# SYSCTL_1.0 register map
Vendor: Texas Instruments
Registers are 32-bit, read-write, no defined reset value unless marked. A register's access mark holds for its fields unless they carry their own. Offsets are as the file gives them; [hi:lo] are bit positions; {n}, {i} and the like mark numbered series; 'fields as' and 'values as' point back to an identical list.

## SYSCTL (part 2 of 2)
0x2018 SYSCTL_BOOTDIAG access not given — 32 bit boot diagnostic to Debugss
0x201C SYSCTL_INFRASTATUS1 ro — Infrastructure Status 2
  [0] CRPAD — Customer Return Pad
0x2020 SYSCTL_FWEPROTMAINA access not given — 1 Sector Write-Erase per bit starting at address 0x0 of flash
0x2024 SYSCTL_FWEPROTMAINB0 access not given — 8xSector Write-Erase per bit starting at address 0x0 of flash
0x2038 SYSCTL_CSC — Customer Startup Code Exists
  [0] DISABLE — BOOTCODE writes 1 to remove CSC handling, default is CSC exists and will be executed
    1=TRUE (CSC DISABLED)
0x203C SYSCTL_DBGCSC — Debug Customer Startup Code
  [0] ON — BOOTCODE writes 1 to indicate that Debug Of CSC is available, left unwritten there will be no CSC debug possible
    1=TRUE
0x2040 SYSCTL_JTAGUSERCODE access not given — JTAG USERCODE
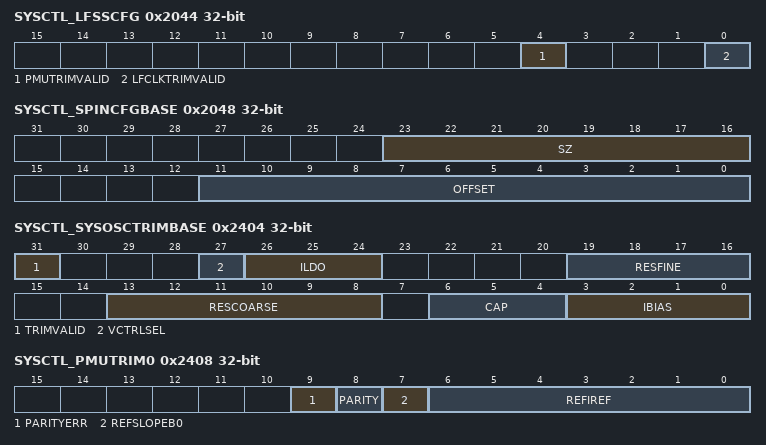
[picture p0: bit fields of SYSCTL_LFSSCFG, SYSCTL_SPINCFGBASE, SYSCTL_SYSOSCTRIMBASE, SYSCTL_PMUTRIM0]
0x2044 SYSCTL_LFSSCFG — LFSS Configuration control
  [4] PMUTRIMVALID — PMU TRIM For VBAT of LFSS is Valid
  [0] LFCLKTRIMVALID — LFCLK TRIM For LFSS is Valid
0x2048 SYSCTL_SPINCFGBASE ro — SPIN Configuration Offset and Size
  [23:16] SZ — Size in number of words of SPIN region including SPINCRC
  [11:0] OFFSET — Offset to start of SPINCFG from TRIMCFG base
0x204C SYSCTL_DEVICE_SUBTYPE — Device Subtype
  [15:0] VALUE
    0x5555=FS (Device is Field Securable); 0x9999=FA (Device Failure Analysis); 0xAAAA=KP (Device Key Provisioned); 0xABCD=SE (Device Security Enforced for all other values)
0x2400 SYSCTL_DMATRIMUNLOCK access not given — DMA TRIM Unlock
0x2404 SYSCTL_SYSOSCTRIMBASE — SYSOSC Trim Values for frequency when change from disable to enable, generally 32MHz
  [31] TRIMVALID — TRIM Data Valid- used to trigger FSM
  [27] VCTRLSEL — VCTRL SEL used potentially needed for FCL mode. Default 0
  [26:24] ILDO — ILDO TRIM -- Only 1 value, Not frequency dependent
  [19:16] RESFINE — Resister Coarse TRIM - Changes per frequency target
  [13:8] RESCOARSE — Resister Coarse TRIM - Changes per frequency target
  [6:4] CAP — CAP TRIM - Changes per frequency target
  [3:0] IBIAS — IBIAS TRIM - Only 1 value, not frequency dependent
0x2408 SYSCTL_PMUTRIM0 access per field — PMU TRIM 0
  [9] PARITYERR ro — Parity Error for PMUTRIM0
  [8] PARITY rw — Parity for PMUTRIM0
  [7] REFSLOPEB0 rw — Reference Slope TRIM Bit0
  [6:0] REFIREF rw — Reference IREF TRIM
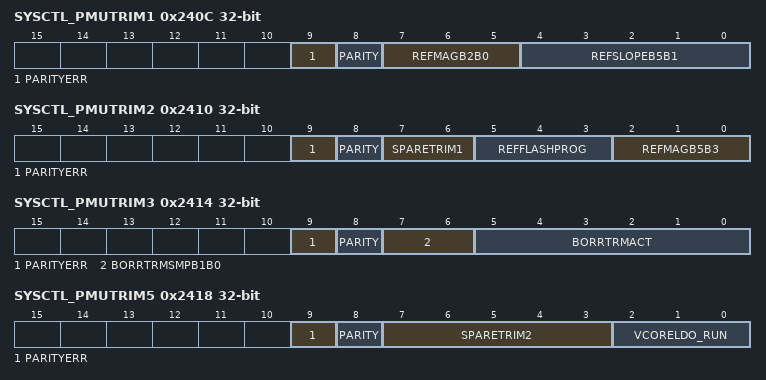
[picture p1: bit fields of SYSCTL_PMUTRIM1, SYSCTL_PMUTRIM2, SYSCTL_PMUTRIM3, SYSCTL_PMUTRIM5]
0x240C SYSCTL_PMUTRIM1 access per field — PMU TRIM 1
  [9] PARITYERR ro — Parity Error for PMUTRIM1
  [8] PARITY rw — Parity for PMUTRIM1
  [7:5] REFMAGB2B0 rw — Reference MAG TRIM Bit2_0
  [4:0] REFSLOPEB5B1 rw — Reference Slope TRIM Bit5_1
0x2410 SYSCTL_PMUTRIM2 access per field — PMU TRIM 2
  [9] PARITYERR ro — Parity Error for PMUTRIM2
  [8] PARITY rw — Parity for PMUTRIM2
  [7:6] SPARETRIM1 rw
  [5:3] REFFLASHPROG rw — Reference Flash Programming
  [2:0] REFMAGB5B3 rw — Reference MAG TRIM Bit5_3
0x2414 SYSCTL_PMUTRIM3 access per field — PMU TRIM 3
  [9] PARITYERR ro — Parity Error for PMUTRIM3
  [8] PARITY rw — Parity for PMUTRIM3
  [7:6] BORRTRMSMPB1B0 rw — BOR R-TRIM for Sampled mode1_0
  [5:0] BORRTRMACT rw — BOR R-TRIM for Active mode
0x2418 SYSCTL_PMUTRIM5 access per field — PMU TRIM 5
  [9] PARITYERR ro — Parity Error for PMUTRIM5
  [8] PARITY rw — Parity for PMUTRIM5
  [7:3] SPARETRIM2 rw
  [2:0] VCORELDO_RUN rw — Voltage Setting for RUN mode
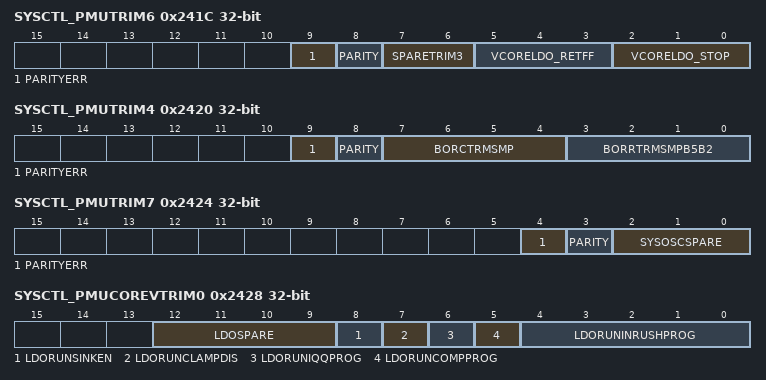
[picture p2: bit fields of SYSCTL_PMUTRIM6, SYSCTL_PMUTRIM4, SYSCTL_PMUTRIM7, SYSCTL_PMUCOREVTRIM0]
0x241C SYSCTL_PMUTRIM6 access per field — PMU TRIM 6
  [9] PARITYERR ro — Parity Error for PMUTRIM6
  [8] PARITY rw — Parity for PMUTRIM6
  [7:6] SPARETRIM3 rw
  [5:3] VCORELDO_RETFF rw — Voltage Setting for retention flop during STOP mode
  [2:0] VCORELDO_STOP rw — Voltage Setting for 10 percent OPP in STOP-STANDBY mode
0x2420 SYSCTL_PMUTRIM4 access per field — PMU TRIM 4
  [9] PARITYERR ro — Parity Error for PMUTRIM4
  [8] PARITY rw — Parity for PMUTRIM4
  [7:4] BORCTRMSMP rw — BOR C-TRIM for Sampled mode3_0
  [3:0] BORRTRMSMPB5B2 rw — BOR R-TRIM for Sampled mode5_2
0x2424 SYSCTL_PMUTRIM7 access per field — PMU TRIM 7
  [4] PARITYERR ro — Parity Error for PMUTRIM7
  [3] PARITY rw — Parity for PMUTRIM7
  [2:0] SYSOSCSPARE rw — Sysosc LDO Spare TRIM
0x2428 SYSCTL_PMUCOREVTRIM0 — PMU CORE VOLTAGE TRIM 0
  [12:9] LDOSPARE — LDO RUN SPARE
  [8] LDORUNSINKEN
  [7] LDORUNCLAMPDIS
  [6] LDORUNIQQPROG
  [5] LDORUNCOMPPROG
  [4:0] LDORUNINRUSHPROG
0x242C SYSCTL_FLASHPUMPTRIML access not given — Flash Pump TRIM-CFG Bits 31...0
0x2430 SYSCTL_FLASHPUMPTRIMH — Flash Pump TRIM-CFG Bits 39...32
  [7:0] DATA — Flash IP determines usage
0x2434 SYSCTL_FLASHBANK0TRIM access not given — $btname TRIM-CFG
0x2438 SYSCTL_FLASHBANK0MPTRIM — $brname Flash MP Trim
  [7:0] DATA — MP Trim Bits
0x243C SYSCTL_FLASHBANK0REPAIR — $brname Flash Repair
  [27:0] DATA — Repair Bits
0x2440 SYSCTL_FLASHBANK1TRIM access not given — $btname TRIM-CFG
0x2444 SYSCTL_FLASHBANK1MPTRIM — $brname Flash MP Trim
  [7:0] DATA — MP Trim Bits
0x2448 SYSCTL_FLASHBANK1REPAIR — $brname Flash Repair
  [27:0] DATA — Repair Bits
0x244C SYSCTL_FLASHBANK2TRIM access not given — $btname Data Bank TRIM-CFG
0x2450 SYSCTL_FLASHBANK2MPTRIM — $brname Flash MP TRIM
  [7:0] DATA — Data Bank MP TRIM Bits
0x2454 SYSCTL_FLASHBANK2REPAIR — $brname Flash Repair
  [27:0] DATA — Data Bank Repair Bits
0x2458 SYSCTL_SRAMREPAIR0 access not given — SRAM Repair 1
0x245C SYSCTL_SRAMREPAIR access not given — SRAM Repair
0x2460 SYSCTL_FLASHSRAMCFG — Flash and SRAM Configuration
  [31] FLTRIMDONE — 1: Flash TRIM bits loaded 0: TRIM unwritten
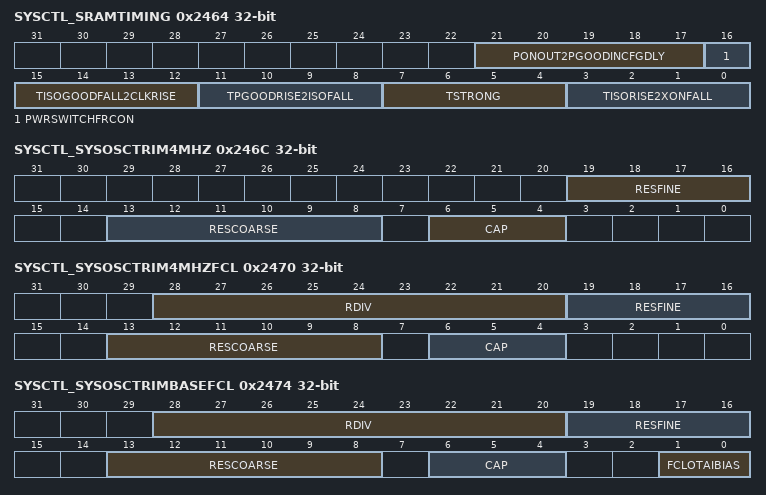
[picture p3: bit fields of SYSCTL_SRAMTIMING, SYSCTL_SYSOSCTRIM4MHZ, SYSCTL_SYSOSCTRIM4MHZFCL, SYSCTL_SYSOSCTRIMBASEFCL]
0x2464 SYSCTL_SRAMTIMING — SRAM timing MMR for ESRAM controller, based on 4MHz
  [21:17] PONOUT2PGOODINCFGDLY — Programmable delay for power switch PONOUT to PGOODIN
  [16] PWRSWITCHFRCON — Debug option to force SVT SRAM PWR Switches always on
  [15:12] TISOGOODFALL2CLKRISE — ISO GOOD FALL to CLKRISE, spec 250ns (boot 500ns)
  [11:8] TPGOODRISE2ISOFALL — PGOOD RISE to ISO FALL, spec 750ns (boot 1500ns)
  [7:4] TSTRONG — Driver Weak to Stong timing, spec 1000ns (boot 1500ns)
  [3:0] TISORISE2XONFALL — ISO Rise to any ON FALL, spec 500ns (boot 750ns)
0x2468 SYSCTL_MCORELDOCFG — LDO Voltage Settings
  [27:24] STOP2RUNDLY — Delay value in usec for STOP voltage to STEP voltage
0x246C SYSCTL_SYSOSCTRIM4MHZ — SYSOSC Trim Values for 4MHz target
  [19:16] RESFINE — Resister Coarse TRIM - Changes per frequency target
  [13:8] RESCOARSE — Resister Coarse TRIM - Changes per frequency target
  [6:4] CAP — CAP TRIM - Changes per frequency target
0x2470 SYSCTL_SYSOSCTRIM4MHZFCL — SYSOSC Trim Values for 4MHz target with FCL enabled
  [28:20] RDIV — FCL RDIV TRIM - Changes per frequency target
  [19:16] RESFINE — Resister Coarse TRIM - Changes per frequency target
  [13:8] RESCOARSE — Resister Coarse TRIM - Changes per frequency target
  [6:4] CAP — CAP TRIM - Changes per frequency target
0x2474 SYSCTL_SYSOSCTRIMBASEFCL — SYSOSC Trim Values for 32MHz target with FCL enabled
  [28:20] RDIV — FCL RDIV TRIM - Changes per frequency target
  [19:16] RESFINE — Resister Fine TRIM - Changes per frequency target
  [13:8] RESCOARSE — Resister Coarse TRIM - Changes per frequency target
  [6:4] CAP — CAP TRIM - Changes per frequency target
  [1:0] FCLOTAIBIAS — FCL IBIAS TRIM, Not frequency dependent
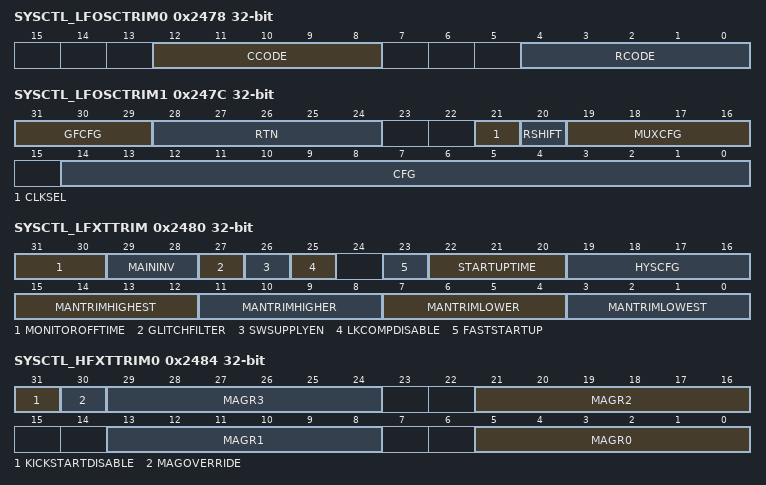
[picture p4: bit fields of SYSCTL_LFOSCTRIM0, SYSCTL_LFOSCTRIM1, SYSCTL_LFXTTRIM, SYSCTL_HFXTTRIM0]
0x2478 SYSCTL_LFOSCTRIM0 — LFOSC TRIM values
  [12:8] CCODE — LFOSC Cap Frequency Trim
  [4:0] RCODE — LFOSC Res Frequency Trim
0x247C SYSCTL_LFOSCTRIM1 — LFOSC TRIM values
  [31:29] GFCFG — LFXT GFCFG - This is hardwired 0 if no LFXT present
  [28:24] RTN — LFOSC Noise Trim
  [21] CLKSEL — 0: divide LFOSC by 2 to give 32KHz, 1: pass through 64KHz
  [20] RSHIFT — LFOSC RSHIFT Trim
  [19:16] MUXCFG — LFOSC Mux CFG Trim
  [14:0] CFG — LFOSC CFG Trim
0x2480 SYSCTL_LFXTTRIM — LFXT TRIM values
  [31:30] MONITOROFFTIME — XT Monitor Off Time Trim
  [29:28] MAININV — LFXT Main Inverter Strength
  [27] GLITCHFILTER — Glitch Filter Enable
    0=DISABLE; 1=ENABLE
  [26] SWSUPPLYEN — LFXT SW Supply Enable
  [25] LKCOMPDISABLE — LFXT Leakage Comp Disable
  [23] FASTSTARTUP — LFXT Fast Startup Select
  [22:20] STARTUPTIME — LFXT Startup Time
  [19:16] HYSCFG — LFXT Hysterisys Config
  [15:12] MANTRIMHIGHEST — LFXT Man Reg Trim Highest Power
  [11:8] MANTRIMHIGHER — LFXT Man Reg Trim Higher Power
  [7:4] MANTRIMLOWER — LFXT Man Reg Trim Lower Power
  [3:0] MANTRIMLOWEST — LFXT Man Reg Trim Lowest Power
0x2484 SYSCTL_HFXTTRIM0 — HFXT TRIM and Override
  [31] KICKSTARTDISABLE — DISABLE Kickstart
    0=FALSE; 1=TRUE
  [30] MAGOVERRIDE — Use this TRIM value instead of hardwired
    0=DISABLE; 1=ENABLE
  [8n+5:8n] MAGR{n} (n=0..3) — Value for MAG TRIM Range {n}
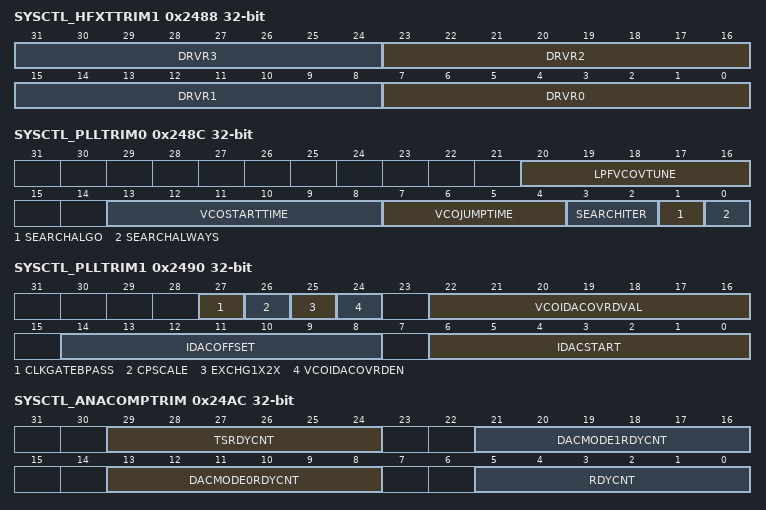
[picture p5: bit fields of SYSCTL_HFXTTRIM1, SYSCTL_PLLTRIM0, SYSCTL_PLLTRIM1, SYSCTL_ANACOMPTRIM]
0x2488 SYSCTL_HFXTTRIM1 — HFXT TRIM and Override
  [8n+7:8n] DRVR{n} (n=0..3) — Value for DRV TRIM Range {n}
0x248C SYSCTL_PLLTRIM0 — PLL TRIM and Override
  [20:16] LPFVCOVTUNE — LPF VCOVTUNE NOM Value
  [13:8] VCOSTARTTIME — VCO Start Settling Time in HFXT 48MHz - this comes before STARTTIME-STARTTIMELP
  [7:4] VCOJUMPTIME — VCO Freq Jump Settling Time
  [3:2] SEARCHITER — Search iterations to perform
    0=OneIteration; 1=TwoIteration; 2=ThreeIteration; 3=FourIteration
  [1] SEARCHALGO — Select Search Mode Algorithm
    0=ALG1; 1=ALG2
  [0] SEARCHALWAYS — Force Freq Search to ALWAYS be performed
    0=DISABLE; 1=ENABLE
0x2490 SYSCTL_PLLTRIM1 — PLL TRIM and Override
  [27] CLKGATEBPASS — Clock Gating Bypass added to SPARE MMR bit 1 port
    0=DISABLE; 1=ENABLE
  [26] CPSCALE — CP Scale added to SPARE MMR bit 0 port
    0=DISABLE; 1=ENABLE
  [25] EXCHG1X2X — Exchange 1X and 2X clock paths - Experimental
    0=DISABLE; 1=ENABLE
  [24] VCOIDACOVRDEN — VCO Feq IDAC mcode override enable
    0=DISABLE; 1=ENABLE
  [22:16] VCOIDACOVRDVAL — VCO Feq IDAC mcode override val
  [14:8] IDACOFFSET — IDAC Offset Value
  [6:0] IDACSTART — IDAC Start Value
0x2494 SYSCTL_M33ADC12B0INLTRIM0 access not given — Bits 31..0 of ADC INL TRIM Instance 0
0x2498 SYSCTL_M33ADC12B0INLTRIM1 — Bits 62..32 of ADC INL TRIM Instance 0
  [30:0] VALUE — Bits 62..32 of ADC INL TRIM
0x249C SYSCTL_M33ADC12B0OFFSETTRIM — Bits 7..0 of ADC OFFSET TRIM Instance 0
  [7:0] VALUE — Bits 62..32 of ADC OFFSET TRIM
0x24A0 SYSCTL_M33ADC12B1INLTRIM0 access not given — Bits 31..0 of ADC INL TRIM Instance 0
0x24A4 SYSCTL_M33ADC12B1INLTRIM1 — Bits 62..32 of ADC INL TRIM Instance 0
  [30:0] VALUE — Bits 62..32 of ADC INL TRIM
0x24A8 SYSCTL_M33ADC12B1OFFSETTRIM — Bits 7..0 of ADC OFFSET TRIM Instance 1
  [7:0] VALUE — Bits 62..32 of ADC OFFSET TRIM
0x24AC SYSCTL_ANACOMPTRIM — Common Trims for Anacomp
  [29:24] TSRDYCNT — TempSense Ready Count in 1 usec resolution
  [21:16] DACMODE1RDYCNT — DAC Ready Count in 1 usec resolution
  [13:8] DACMODE0RDYCNT — DAC Ready Count in 250ns usec resolution
  [5:0] RDYCNT — Ready Count in 1 usec resolution
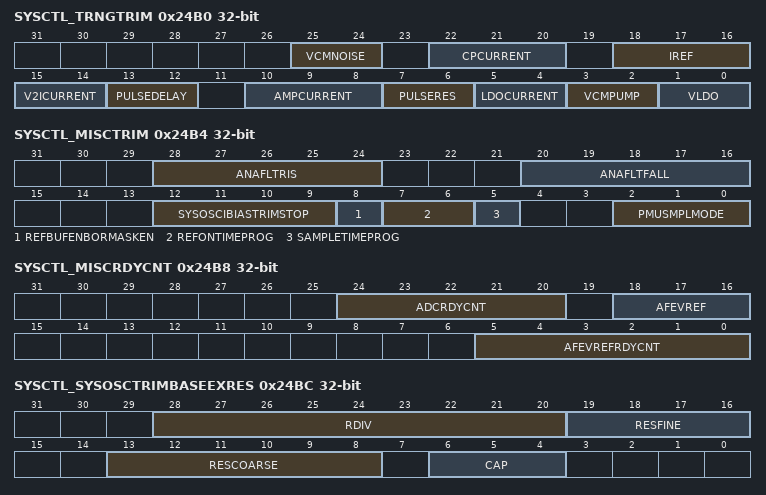
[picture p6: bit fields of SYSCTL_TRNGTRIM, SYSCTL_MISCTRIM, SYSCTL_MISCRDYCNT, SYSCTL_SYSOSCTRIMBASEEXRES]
0x24B0 SYSCTL_TRNGTRIM — Trim for TRNG
  [25:24] VCMNOISE — TRNG VCM Noise TRIM
  [22:20] CPCURRENT — TRNG CP Current TRIM
  [18:16] IREF — TRNG IREF TRIM
  [15:14] V2ICURRENT — TRNG V2i Current TRIM
  [13:12] PULSEDELAY — TRNG Pulse Delay TRIM
  [10:8] AMPCURRENT — TRNG Amp Current TRIM
  [7:6] PULSERES — TRNG Pulse Res TRIM
  [5:4] LDOCURRENT — TRNG LDO Current TRIM
  [3:2] VCMPUMP — TRNG VCM Pump TRIM
  [1:0] VLDO — TRNG VLDO TRIM
0x24B4 SYSCTL_MISCTRIM — Various Small TRIM
  [28:24] ANAFLTRIS — Analog GlitchFilter Rising Trim
  [20:16] ANAFLTFALL — Analog GlitchFilter Falling Trim
  [12:9] SYSOSCIBIASTRIMSTOP — IBIAS TRIM - in STOP mode, oscillator accuracy
  [8] REFBUFENBORMASKEN — BOR Mask Enable
    0=BORMASKDISABLE (BOR Masking disabled when REFBUF is enabled); 1=BORMASKENABLE (BOR Masking enabled when REFBUF is enabled)
  [7:6] REFONTIMEPROG — PMU Ref On Time Programmability TRIM for STANDBY Mode
    {v}=REFONTIME{v+3}CLOCKS (Ref On Time is {v+3} Clocks) (v=0..3)
  [5] SAMPLETIMEPROG — PMU Sample Time Programmability TRIM for STANDBY Mode
    0=SMPLTIME1CLOCK (Sample Time is 1 Clock); 1=SMPLTIME2CLOCKS (Sample Time is 2 Clocks)
  [2:0] PMUSMPLMODE — PMU REF/BOR Sample Periode TRIM for STANDBY Mode
    0=SMPL8MS (Sample Periode is 8ms); 1=SMPL16MS (Sample Periode is 16ms); 2=SMPL32MS (Sample Periode is 32ms); 3=SMPL48MS (Sample Periode is 48ms); 4=SMPL64MS (Sample Periode is 64ms); 5=SMPL80MS (Sample Periode is 80ms); 6=SMPL100MS (Sample Periode is 100ms); 7=SMPL125MS (Sample Periode is 125ms)
0x24B8 SYSCTL_MISCRDYCNT — Various Small RDY CNT or other familiy TRIM
  [24:20] ADCRDYCNT — Ready Count in 1 usec resolution
  [18:16] AFEVREF — VREF TRIM
  [5:0] AFEVREFRDYCNT — VREF Ready Count Nano is in 1 usec, Micro in 8 usec resolution
0x24BC SYSCTL_SYSOSCTRIMBASEEXRES — SYSOSC Trim Values for BASE frequency external resistor FCL
  [28:20] RDIV — External Resistor feature Not used
  [19:16] RESFINE — External Resistor feature Not used
  [13:8] RESCOARSE — External Resistor feature Not used
  [6:4] CAP — External Resistor feature Not used
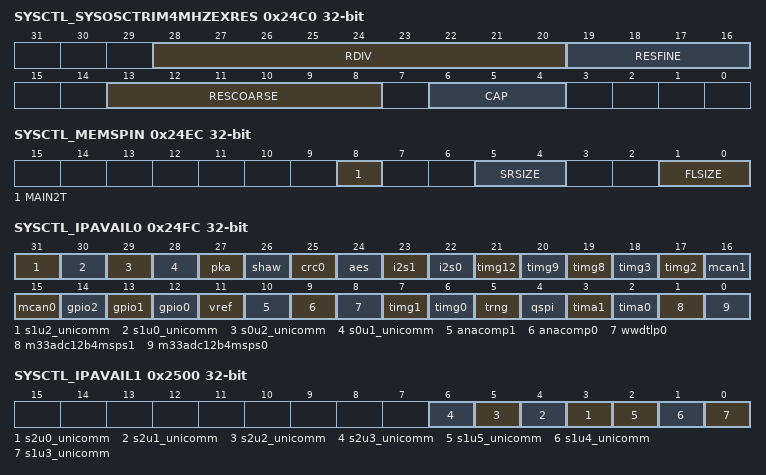
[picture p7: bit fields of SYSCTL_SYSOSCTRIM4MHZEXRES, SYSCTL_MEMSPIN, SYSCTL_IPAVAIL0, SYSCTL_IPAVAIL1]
0x24C0 SYSCTL_SYSOSCTRIM4MHZEXRES — SYSOSC Trim Values for 4MHz frequency external resistor FCL
  fields as SYSCTL_SYSOSCTRIMBASEEXRES
0x24C4 SYSCTL_ANACOMP0TRIM — Per Instance TRIM for ANACOMP0
  [6:0] DATA — TRIM value
0x24C8 SYSCTL_ANACOMP1TRIM — Per Instance TRIM for ANACOMP1
  [6:0] DATA — TRIM value
0x24CC SYSCTL_VBATPMUTRIM0 access not given — VBAT PMU TRIM lower 32bits
0x24D0 SYSCTL_VBATPMUTRIM1 — VBAT PMU TRIM Bits 42-32
  [10:0] DATA — Bits 42-32 VBAT PMU TRIM
0x24D4 SYSCTL_M33C1SPARETRIM1 access not given — M33C1 Spare TRIM1
0x24D8 SYSCTL_M33C1SPARETRIM2 access not given — M33C1 Spare TRIM2
0x24DC SYSCTL_ULLSYSOSC — SYSOSC Spare TRIM
  [2:0] SPARE — Sysosc Spare Trim
0x24E0 SYSCTL_M33C1SPAREREG access not given — Spare Register Read only
0x24E4 SYSCTL_PROBECRC access not given — FINAL 32 bit CRC of the PROBE TRIM load
0x24E8 SYSCTL_SPINUNLOCK access not given — SPIN Region Unlock Signiture: 0x5F689B9D always reads this value
0x24EC SYSCTL_MEMSPIN — Flash and SRAM Configuration
  [8] MAIN2T — 1: Main (nonmain) are 2T access 0: Main (nonmain) are 1T access
  [5:4] SRSIZE — SRAM Paper Spin 0: Full size, 1: 1/2, 2: 1/4
  [1:0] FLSIZE — Flash Paper Spin 0: Full size, 1: 1/2, 2: 1/4
0x24F0 SYSCTL_PADNOTAVAIL0 access not given — PAD Exist for IOMUX
0x24F4 SYSCTL_PADNOTAVAIL1 access not given — PAD Exist for IOMUX
0x24F8 SYSCTL_PADNOTAVAIL2 — PAD Exist for IOMUX
  [28:0] DATA — Padexists Vector bits- 0: Pad Available 1: Pad Not Available
0x24FC SYSCTL_IPAVAIL0 — IP Available Paper Spin
  [all] fields
    0=NOTAVAILABLE; 1=AVAILABLE
  [31] s1u2_unicomm — Bit field is not used
  [30] s1u0_unicomm — Bit field is not used
  [29] s0u2_unicomm — Bit field is not used
  [28] s0u1_unicomm — Bit field is not used
  [27] pka — Peripheral Instance Available
  [26] shaw — Peripheral Instance Available
  [25] crc0 — Peripheral Instance Available
  [24] aes — Bit field is not used
  [23] i2s1 — Bit field is not used
  [22] i2s0 — Bit field is not used
  [21] timg12 — Bit field is not used
  [20] timg9 — Bit field is not used
  [19] timg8 — Bit field is not used
  [18] timg3 — Bit field is not used
  [17] timg2 — Bit field is not used
  [16] mcan1 — Peripheral Instance Available
  [15] mcan0 — Peripheral Instance Available
  [14] gpio2 — Bit field is not used
  [13] gpio1 — Bit field is not used
  [12] gpio0 — Bit field is not used
  [11] vref — Bit field is not used
  [10] anacomp1 — Bit field is not used
  [9] anacomp0 — Bit field is not used
  [8] wwdtlp0 — Bit field is not used
  [7] timg1 — Bit field is not used
  [6] timg0 — Bit field is not used
  [5] trng — Bit field is not used
  [4] qspi — Bit field is not used
  [3] tima1 — Bit field is not used
  [2] tima0 — Bit field is not used
  [1] m33adc12b4msps1 — Bit field is not used
  [0] m33adc12b4msps0 — Bit field is not used
0x2500 SYSCTL_IPAVAIL1 — IP Available Paper Spin
  [all] fields
    0=NOTAVAILABLE; 1=AVAILABLE
  [n+3] s2u{n}_unicomm (n=0..3) — Peripheral Instance Available
  [2] s1u5_unicomm — Peripheral Instance Available
  [1] s1u4_unicomm — Peripheral Instance Available
  [0] s1u3_unicomm — Peripheral Instance Available
0x2504 SYSCTL_FUNCPSPIN — Functional Paper Spin Options
  [0] MCANFD — MCAN FD enabled
0x2508 SYSCTL_TRIMCRC access not given — FINAL 32 bit CRC of the SPIN load
0x2800 SYSCTL_MGMT_M33ADC12B4MSPS1_PWREN — IP Enable Register
  [0] ENABLE — IP Enable
    0=Disable; 1=Enable
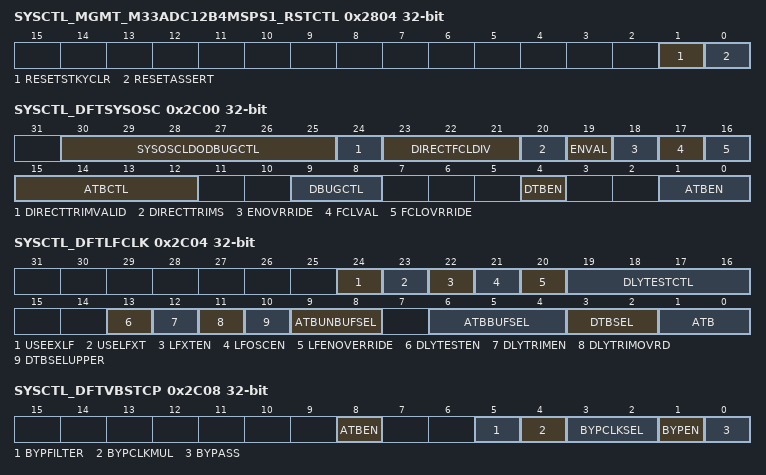
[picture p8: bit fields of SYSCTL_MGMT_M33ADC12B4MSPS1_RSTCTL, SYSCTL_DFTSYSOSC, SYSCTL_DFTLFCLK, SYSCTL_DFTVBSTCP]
0x2804 SYSCTL_MGMT_M33ADC12B4MSPS1_RSTCTL — Power Control Register - Write Only Register, Always Read as 0
  [1] RESETSTKYCLR — Clear the RESET STICKY Bit
    1=Clear
  [0] RESETASSERT — Assert Reset to IP Domain.
    1=Do
0x2814 SYSCTL_MGMT_M33ADC12B4MSPS1_STAT ro — IP State Register - Read Only
  [16] RESETSTKY — IP has been Reset
    0=clear; 1=Set
0x2C00 SYSCTL_DFTSYSOSC — DFT Control for SYSOSC
  [30:25] SYSOSCLDODBUGCTL — SYSOSC LDO DBUG CTL Direct to MSIP
  [24] DIRECTTRIMVALID — TRIMVALID MSIP input value when DIRECTTRIMS is 1
  [23:21] DIRECTFCLDIV — FCL DIV value when DIRECTTRIMS is 1
  [20] DIRECTTRIMS — MUX SYSOSCBASE MMR values directly to MSIP input and hold SWITCHFREQ 1
  [19] ENVAL — Override Value for the functional Enable into the MSIP
  [18] ENOVRRIDE — Override the functional Enable with ENVAL into the MSIP
  [17] FCLVAL — Override Value for the functional FCL Enable into the MSIP
  [16] FCLOVRRIDE — Override the functional FCL Enable with FCLVAL into the MSIP
  [15:12] ATBCTL — ATB Control - Direct to MSIP
  [9:8] DBUGCTL — Debug Control - Direct to MSIP
  [4] DTBEN — Enable DTB Structure - Direct to MSIP
    0=DISABLE; 1=ENABLE
  [1:0] ATBEN — Enable ATB Structure - Direct to MSIP
0x2C04 SYSCTL_DFTLFCLK — DFT Control for LFCLK Hard Macro
  [24] USEEXLF — Value for USEEXLF when LFENOVERRIDE is set
  [23] USELFXT — Value for USELFXT when LFENOVERRIDE is set
  [22] LFXTEN — Value for LFXT_EN when LFENOVERRIDE is set
  [21] LFOSCEN — Value for LFOSC_EN when LFENOVERRIDE is set
  [20] LFENOVERRIDE — Override the functional LFOSC - LFXT enable
  [19:16] DLYTESTCTL — Delay Cell Test CTL - Direct to MSIP
  [13] DLYTESTEN — WHEN DLYTRIMOVRD - DLYTESTEN - ELSE 0 for Delay Cell Test Enable
  [12] DLYTRIMEN — WHEN DLYTRIMOVRD - DLYTRIMEN - ELSE 1 for Delay Cell Trim Enable
  [11] DLYTRIMOVRD — Delay Cell Trim OVERRIDE control
  [10] DTBSELUPPER — DTB Select for Upper 4 bits of DTBO[11:0] of hard macro
  [9:8] ATBUNBUFSEL — ATB Buffered Signal Select - Direct to MSIP
  [6:4] ATBBUFSEL — ATB Buffered Signal Select - Direct to MSIP
  [3:2] DTBSEL — DTB Select at hard macro - Direct to MSIP
  [1:0] ATB — Bit1: enables buffered path, Bit0 enables unbuffered path - Direct to MSIP
0x2C08 SYSCTL_DFTVBSTCP — DFT for VBOOST Charge Pump
  [8] ATBEN — This forces CPUMP enabled as part of the larger enable equation it is not the dedicated override
    0=DISABLE; 1=ENABLE
  [5] BYPFILTER — No filter makes power up faster
    0=DISABLE; 1=ENABLE
  [4] BYPCLKMUL — Multiply CP clk by 8
    0=DISABLE; 1=ENABLE
  [3:2] BYPCLKSEL — CP Clock Select
    0=CLK4MHZ; 2=CLK32KHZ; 3=DTBI0
  [1] BYPEN — EN to Hard Macro
    0=DISABLE; 1=ENABLE
  [0] BYPASS — Override enable for BYPCLKMUL, BYPFILTER, BYPEN, BYPCLKSEL
    0=DISABLE; 1=ENABLE
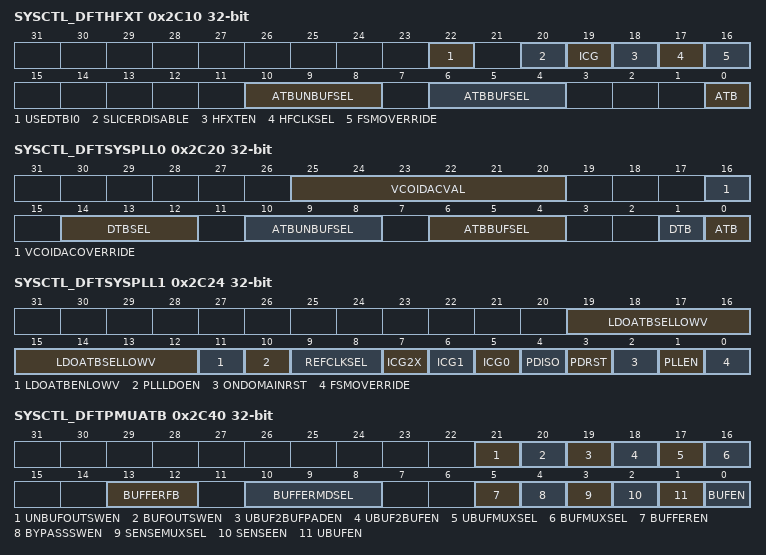
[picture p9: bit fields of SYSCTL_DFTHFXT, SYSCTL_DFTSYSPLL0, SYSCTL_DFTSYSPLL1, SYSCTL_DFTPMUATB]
0x2C10 SYSCTL_DFTHFXT — DFT Control for HFXT
  [22] USEDTBI0 — Use DTBI[0] as the HFCLK output - does not require FSMOVERRIDE
    0=FALSE; 1=TRUE
  [20] SLICERDISABLE — Turn off slicer - Direct to MSIP
    0=FALSE; 1=TRUE
  [19] ICG — Override value when FSMOVERRIDE to turn HFCLK related ICGs ON qualified with HFCLKSEL
    0=DISABLE; 1=ENABLE
  [18] HFXTEN — Override value when FSMOVERRIDE for HFXT ENABLE to Hard Macro
    0=DISABLE; 1=ENABLE
  [17] HFCLKSEL — Override value when FSMOVERRIDE for High Frequency Oscillator Source(HFCLK)
    0=HFXT; 1=EXTHF
  [16] FSMOVERRIDE — Override outputs of HFCLK FSM-ATTEST must also be TRUE
    0=DISABLE; 1=ENABLE
  [10:8] ATBUNBUFSEL — ATB Buffered Signal Select - Direct to MSIP
  [6:4] ATBBUFSEL — ATB Buffered Signal Select - Direct to MSIP
  [0] ATB — Enable ATB Structure - Direct to MSIP
    0=DISABLE; 1=ENABLE
0x2C20 SYSCTL_DFTSYSPLL0 — DFT Control for SYSPLL
  [25:20] VCOIDACVAL — Override Value For VCO Freq Idac Code - Direct to MSIP
  [16] VCOIDACOVERRIDE — Override Enable For VCO Freq Idac Code - Direct to MSIP
    0=DISABLE; 1=ENABLE
  [14:12] DTBSEL — DTB Signal Select - Direct to MSIP
  [10:8] ATBUNBUFSEL — ATB UnBuffered Signal Select - Direct to MSIP
  [6:4] ATBBUFSEL — ATB Buffered Signal Select - Direct to MSIP
  [1] DTB — Enable DTB Structure - Direct to MSIP
    0=DISABLE; 1=ENABLE
  [0] ATB — Enable ATB Structure - Direct to MSIP
    0=DISABLE; 1=ENABLE
0x2C24 SYSCTL_DFTSYSPLL1 — DFT Control for SYSPLL
  [19:12] LDOATBSELLOWV — LDO ATB mux selection - Direct to MSIP
  [11] LDOATBENLOWV — LDO ATB mux enable - Direct to MSIP
  [10] PLLLDOEN — Override value when FSMOVERRIDE for PLL LDO ENABLE to PLL
    0=DISABLE; 1=ENABLE
  [9:8] REFCLKSEL — Override value when FSMOVERRIDE Override value to select Ref Clk
    0=SYSOSC; 1=HFCLK; 2=DTBI0
  [7] ICG2X — Override value when FSMOVERRIDE Override value to turn PLL ICGCLK2X ON
    0=DISABLE; 1=ENABLE
  [6] ICG1 — Override value when FSMOVERRIDE Override value to turn PLL ICGCLK1 ON
    0=DISABLE; 1=ENABLE
  [5] ICG0 — Override value when FSMOVERRIDE Override value to turn PLL ICGCLK0 ON
    0=DISABLE; 1=ENABLE
  [4] PDISO — Override value when FSMOVERRIDE Assert ISO PD to the hard macro
    0=DEASSERT; 1=ASSERT
  [3] PDRST — Override value when FSMOVERRIDE Assert RST PD to the hard macro
    0=DEASSERT; 1=ASSERT
  [2] ONDOMAINRST — Override value when FSMOVERRIDE Assert ONDOMAIN RST to the hard macro
    0=DEASSERT; 1=ASSERT
  [1] PLLEN — Override value when FSMOVERRIDE for PLL ENABLE to PLL
    0=DISABLE; 1=ENABLE
  [0] FSMOVERRIDE — Override outputs of PLL FSM-ATTEST must also be TRUE
    0=DISABLE; 1=ENABLE
0x2C40 SYSCTL_DFTPMUATB — DFT Control for PMU ATB
  [21] UNBUFOUTSWEN
    0=DISABLE; 1=ENABLE
  [20] BUFOUTSWEN
    0=DISABLE; 1=ENABLE
  [19] UBUF2BUFPADEN
    0=DISABLE; 1=ENABLE
  [18] UBUF2BUFEN
    0=DISABLE; 1=ENABLE
  [17] UBUFMUXSEL
    0=DISABLE; 1=ENABLE
  [16] BUFMUXSEL
    0=DISABLE; 1=ENABLE
  [13:12] BUFFERFB
  [10:8] BUFFERMDSEL
  [5] BUFFEREN
    0=DISABLE; 1=ENABLE
  [4] BYPASSSWEN
    0=DISABLE; 1=ENABLE
  [3] SENSEMUXSEL
    0=DISABLE; 1=ENABLE
  [2] SENSEEN
    0=DISABLE; 1=ENABLE
  [1] UBUFEN — ATB UnBuffered Output Enable
    0=DISABLE; 1=ENABLE
  [0] BUFEN — ATB Buffered Output Enable
    0=DISABLE; 1=ENABLE
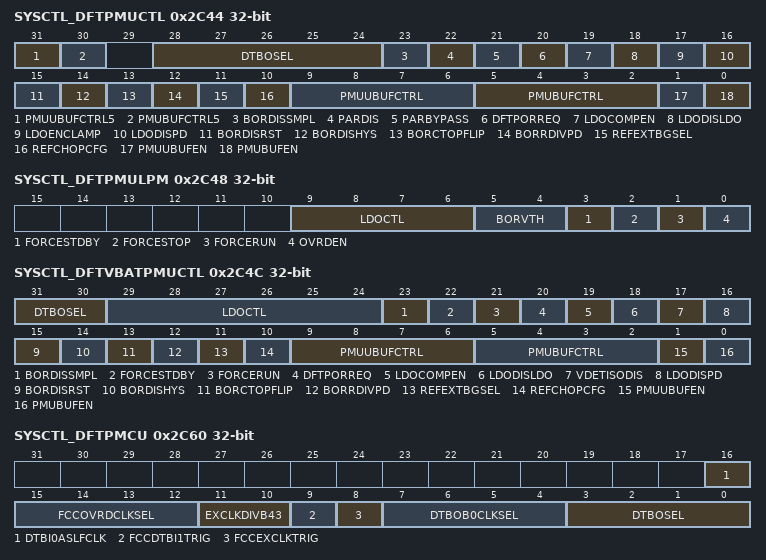
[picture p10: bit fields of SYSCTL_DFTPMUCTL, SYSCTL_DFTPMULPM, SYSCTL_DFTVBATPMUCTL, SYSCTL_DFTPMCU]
0x2C44 SYSCTL_DFTPMUCTL — DFT Control for PMU CTL
  [31] PMUUBUFCTRL5
  [30] PMUBUFCTRL5
  [28:24] DTBOSEL
  [23] BORDISSMPL
    0=DISABLE; 1=ENABLE
  [22] PARDIS
    0=DISABLE; 1=ENABLE
  [21] PARBYPASS
    0=DISABLE; 1=ENABLE
  [20] DFTPORREQ
    0=DISABLE; 1=ENABLE
  [19] LDOCOMPEN
    0=DISABLE; 1=ENABLE
  [18] LDODISLDO
    0=DISABLE; 1=ENABLE
  [17] LDOENCLAMP
    0=DISABLE; 1=ENABLE
  [16] LDODISPD
    0=DISABLE; 1=ENABLE
  [15] BORDISRST
    0=DISABLE; 1=ENABLE
  [14] BORDISHYS
    0=DISABLE; 1=ENABLE
  [13] BORCTOPFLIP
    0=DISABLE; 1=ENABLE
  [12] BORRDIVPD
    0=DISABLE; 1=ENABLE
  [11] REFEXTBGSEL
    0=DISABLE; 1=ENABLE
  [10] REFCHOPCFG
    0=DISABLE; 1=ENABLE
  [9:6] PMUUBUFCTRL
  [5:2] PMUBUFCTRL
  [1] PMUUBUFEN — ATB UnBuffered Output Enable
    0=DISABLE; 1=ENABLE
  [0] PMUBUFEN — ATB Buffered Output Enable
    0=DISABLE; 1=ENABLE
0x2C48 SYSCTL_DFTPMULPM — DFT Control for PMU LPM
  [9:6] LDOCTL
  [5:4] BORVTH
  [3] FORCESTDBY
    0=DISABLE; 1=ENABLE
  [2] FORCESTOP
    0=DISABLE; 1=ENABLE
  [1] FORCERUN
    0=DISABLE; 1=ENABLE
  [0] OVRDEN
    0=DISABLE; 1=ENABLE
0x2C4C SYSCTL_DFTVBATPMUCTL — DFT Control for PMU CTL
  [31:30] DTBOSEL
  [29:24] LDOCTL
  [23] BORDISSMPL
    0=DISABLE; 1=ENABLE
  [22] FORCESTDBY
    0=DISABLE; 1=ENABLE
  [21] FORCERUN
    0=DISABLE; 1=ENABLE
  [20] DFTPORREQ
    0=DISABLE; 1=ENABLE
  [19] LDOCOMPEN
    0=DISABLE; 1=ENABLE
  [18] LDODISLDO
    0=DISABLE; 1=ENABLE
  [17] VDETISODIS
    0=DISABLE; 1=ENABLE
  [16] LDODISPD
    0=DISABLE; 1=ENABLE
  [15] BORDISRST
    0=DISABLE; 1=ENABLE
  [14] BORDISHYS
    0=DISABLE; 1=ENABLE
  [13] BORCTOPFLIP
    0=DISABLE; 1=ENABLE
  [12] BORRDIVPD
    0=DISABLE; 1=ENABLE
  [11] REFEXTBGSEL
    0=DISABLE; 1=ENABLE
  [10] REFCHOPCFG
    0=DISABLE; 1=ENABLE
  [9:6] PMUUBUFCTRL
  [5:2] PMUBUFCTRL
  [1] PMUUBUFEN — ATB UnBuffered Output Enable
    0=DISABLE; 1=ENABLE
  [0] PMUBUFEN — ATB Buffered Output Enable
    0=DISABLE; 1=ENABLE
0x2C50 SYSCTL_DFTVBATCTL — DFT Control for VBAT POR
  [0] POR2PADEN — DFT VBAT POR control
    0=DISABLE; 1=ENABLE
0x2C58 SYSCTL_DFTSRAMREPCLR — Clear SRAM Repair Data
  [0] MANCLR — Send CLR to SRAM Banks
    1=TRUE
0x2C60 SYSCTL_DFTPMCU — Overall PMCU DFT Controls
  [16] DTBI0ASLFCLK — Use DTBI0 as the LFCLK source
    0=DISABLE; 1=ENABLE
  [15:12] FCCOVRDCLKSEL — DFT selections for CLK source of counter
    0=FCCSELCLK; 1=DTBI0; 2=ADC0OSCLK; 3=ADC1OSCLK; 4=RAWSYSOSC (Directly from MSIP)
  [11:10] EXCLKDIVB43 — Extends the EXCLK divider by 2 MSB to give div64
  [9] FCCDTBI1TRIG — Use DTBI1 as the trigger
    0=DISABLE; 1=ENABLE
  [8] FCCEXCLKTRIG — Use EXCLK as the trigger
    0=DISABLE; 1=ENABLE
  [7:4] DTBOB0CLKSEL — DFT selections for OTHERCLKS bit 0 of DTB
    0=VBST4MHZCLK; 1=PMUCHOPCLK; 2=FINALVBSTCLK; 3=FUNCEXTCLK
  [3:0] DTBOSEL — Major DTB Output Select
    0=PMU; 1=SYSPLL; 2=LFCLK; 3=OTHERCLKS; 4=SYSOSC
0x2C70 SYSCTL_DFTSRAMREPSHFT0 access not given — Shift SRAM Repair Preamble Read-Only
0x2C78 SYSCTL_DFTSRAMREPSHFT access not given — Shift SRAM Repair Preamble Read-Only
0x3000 SYSCTL_FWEPROTMAIN access not given — 1 Sector Write-Erase per bit starting at address 0x0 of flash
0x3014 SYSCTL_FWPROTMAINDATA — Read-Write Protection for first 4 Sectors of Data Bank
  [7:0] DATA — 00: Both RW allowed 01: Read Only 10: No Read No Write 11: No Read No Write - Not Used
0x3018 SYSCTL_FRXPROTMAINSTART — Flash RX Protection Start Address
  [21:6] ADDR — Flash RX Protection Start Address 64B granularity
0x301C SYSCTL_FRXPROTMAINEND — Flash RX Protection End Address
  [21:6] ADDR — Flash RX Protection End Address 64B granularity
0x3020 SYSCTL_FIPPROTMAINSTART — Flash IP Protection Start Address
  [21:6] ADDR — Flash IP Protection Start Address 64B granularity
0x3024 SYSCTL_FIPPROTMAINEND — Flash IP Protection End Address
  [21:6] ADDR — Flash IP Protection End Address 64B granularity
0x3038 SYSCTL_FLBANKSWPPOLICY — Flash Bank Swap Policy
  [0] DISABLE — 1: Disables Policy To Allow Flash Bank Swapping
    1=TRUE (Disallow Bank Swap)
0x303C SYSCTL_FLBANKSWP — Flash MAIN bank address swap
  [0] USEUPPER — 1: Use Upper Bank as Logical 0
    0=DISABLE (Normal (default) memory map addressing scheme); 1=ENABLE (Flash upper region address space swapped with lower region)
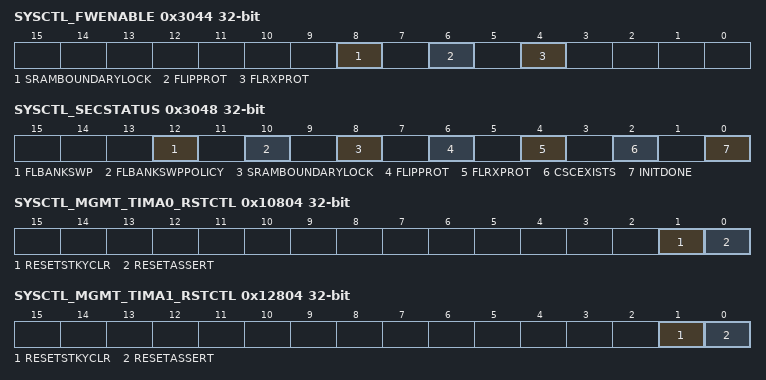
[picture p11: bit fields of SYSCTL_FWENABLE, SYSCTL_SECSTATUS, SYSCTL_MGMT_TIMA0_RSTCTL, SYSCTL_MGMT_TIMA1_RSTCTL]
0x3044 SYSCTL_FWENABLE — Security Firewall Enable Register
  [8] SRAMBOUNDARYLOCK — 1: Blocks Writes from Changing SRAMBOUNDARY MMR
    1=ENABLE (SRAMBOUNDARY MMR Locked)
  [6] FLIPPROT — 1: Flash Read IP ProtectionActive
    1=ENABLE (Turn On Flash IP Protection)
  [4] FLRXPROT — 1: Flash Read Execute Protection Active
    1=ENABLE (Turn On Flash Read-eXecute Protection)
0x3048 SYSCTL_SECSTATUS ro — Security Configuration status
  [12] FLBANKSWP — 1: Upper and Lower Banks have been swapped
  [10] FLBANKSWPPOLICY — 1: Upper and Lower Banks allowed to be swapped
    0=DISABLED; 1=ENABLED
  [8] SRAMBOUNDARYLOCK — Not used
    0=DISABLED; 1=ENABLED
  [6] FLIPPROT — Not used
    0=DISABLED; 1=ENABLED
  [4] FLRXPROT — Not used
    0=DISABLED; 1=ENABLED
  [2] CSCEXISTS — 1: CSC Exists in the system
    0=NO (System does not have a CSC); 1=YES (System does have a CSC)
  [0] INITDONE — 1: CSC has been completed
    0=NO (INIT is not yet done); 1=YES (INIT is done)
0x3060 SYSCTL_INITDONE — INITCODE PASS
  [0] PASS — INITCODE writes 1 for PASS, left unwritten a timeout will occur if not blocked
    1=TRUE (INITCODE PASS)
0x10800 SYSCTL_MGMT_TIMA0_PWREN — IP Enable Register
  [0] ENABLE — IP Enable
    0=Disable; 1=Enable
0x10804 SYSCTL_MGMT_TIMA0_RSTCTL — Power Control Register - Write Only Register, Always Read as 0
  fields as SYSCTL_MGMT_M33ADC12B4MSPS1_RSTCTL
0x10814 SYSCTL_MGMT_TIMA0_STAT ro — IP State Register - Read Only
  [16] RESETSTKY — IP has been Reset
    0=clear; 1=Set
0x12800 SYSCTL_MGMT_TIMA1_PWREN — IP Enable Register
  [0] ENABLE — IP Enable
    0=Disable; 1=Enable
0x12804 SYSCTL_MGMT_TIMA1_RSTCTL — Power Control Register - Write Only Register, Always Read as 0
  fields as SYSCTL_MGMT_M33ADC12B4MSPS1_RSTCTL
0x12814 SYSCTL_MGMT_TIMA1_STAT ro — IP State Register - Read Only
  [16] RESETSTKY — IP has been Reset
    0=clear; 1=Set
0x32800 SYSCTL_MGMT_QSPI_PWREN — IP Enable Register
  [0] ENABLE — IP Enable
    0=Disable; 1=Enable
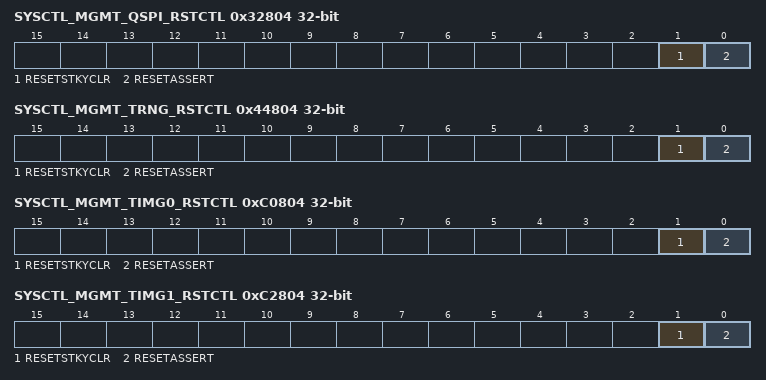
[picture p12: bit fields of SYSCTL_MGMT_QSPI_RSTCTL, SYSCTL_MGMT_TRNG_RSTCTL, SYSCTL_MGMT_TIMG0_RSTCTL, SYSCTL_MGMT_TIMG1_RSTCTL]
0x32804 SYSCTL_MGMT_QSPI_RSTCTL — Power Control Register - Write Only Register, Always Read as 0
  fields as SYSCTL_MGMT_M33ADC12B4MSPS1_RSTCTL
0x32814 SYSCTL_MGMT_QSPI_STAT ro — IP State Register - Read Only
  [16] RESETSTKY — IP has been Reset
    0=clear; 1=Set
0x44800 SYSCTL_MGMT_TRNG_PWREN — IP Enable Register
  [0] ENABLE — IP Enable
    0=Disable; 1=Enable
0x44804 SYSCTL_MGMT_TRNG_RSTCTL — Power Control Register - Write Only Register, Always Read as 0
  fields as SYSCTL_MGMT_M33ADC12B4MSPS1_RSTCTL
0x44814 SYSCTL_MGMT_TRNG_STAT ro — IP State Register - Read Only
  [16] RESETSTKY — IP has been Reset
    0=clear; 1=Set
0x94808 SYSCTL_MGMT_RTC_CLKCFG — IP Clock Configuration Register
  [8] BLOCKASYNC — Async Clock Request is blocked from starting SYSOSC or forcing bus clock to 32MHz
    0=Disable; 1=Enable
0xC0800 SYSCTL_MGMT_TIMG0_PWREN — IP Enable Register
  [0] ENABLE — IP Enable
    0=Disable; 1=Enable
0xC0804 SYSCTL_MGMT_TIMG0_RSTCTL — Power Control Register - Write Only Register, Always Read as 0
  fields as SYSCTL_MGMT_M33ADC12B4MSPS1_RSTCTL
0xC0814 SYSCTL_MGMT_TIMG0_STAT ro — IP State Register - Read Only
  [16] RESETSTKY — IP has been Reset
    0=clear; 1=Set
0xC2800 SYSCTL_MGMT_TIMG1_PWREN — IP Enable Register
  [0] ENABLE — IP Enable
    0=Disable; 1=Enable
0xC2804 SYSCTL_MGMT_TIMG1_RSTCTL — Power Control Register - Write Only Register, Always Read as 0
  fields as SYSCTL_MGMT_M33ADC12B4MSPS1_RSTCTL
0xC2814 SYSCTL_MGMT_TIMG1_STAT ro — IP State Register - Read Only
  [16] RESETSTKY — IP has been Reset
    0=clear; 1=Set
0xD0800 SYSCTL_MGMT_WWDTLP0_PWREN — IP Enable Register
  [0] ENABLE — IP Enable
    0=Disable; 1=Enable
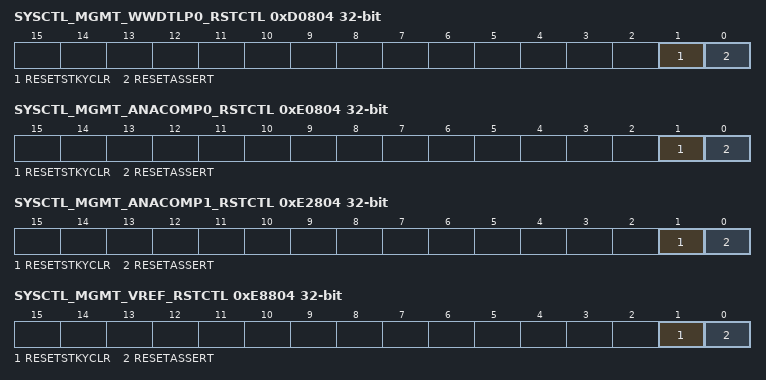
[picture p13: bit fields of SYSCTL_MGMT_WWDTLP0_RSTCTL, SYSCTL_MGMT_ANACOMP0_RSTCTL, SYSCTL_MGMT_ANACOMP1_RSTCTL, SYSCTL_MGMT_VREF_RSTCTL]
0xD0804 SYSCTL_MGMT_WWDTLP0_RSTCTL — Power Control Register - Write Only Register, Always Read as 0
  fields as SYSCTL_MGMT_M33ADC12B4MSPS1_RSTCTL
0xD0814 SYSCTL_MGMT_WWDTLP0_STAT ro — IP State Register - Read Only
  [16] RESETSTKY — IP has been Reset
    0=clear; 1=Set
0xE0800 SYSCTL_MGMT_ANACOMP0_PWREN — IP Enable Register
  [0] ENABLE — IP Enable
    0=Disable; 1=Enable
0xE0804 SYSCTL_MGMT_ANACOMP0_RSTCTL — Power Control Register - Write Only Register, Always Read as 0
  fields as SYSCTL_MGMT_M33ADC12B4MSPS1_RSTCTL
0xE0808 SYSCTL_MGMT_ANACOMP0_CLKCFG — IP Clock Configuration Register
  fields as SYSCTL_MGMT_RTC_CLKCFG
0xE0814 SYSCTL_MGMT_ANACOMP0_STAT ro — IP State Register - Read Only
  [16] RESETSTKY — IP has been Reset
    0=clear; 1=Set
0xE2800 SYSCTL_MGMT_ANACOMP1_PWREN — IP Enable Register
  [0] ENABLE — IP Enable
    0=Disable; 1=Enable
0xE2804 SYSCTL_MGMT_ANACOMP1_RSTCTL — Power Control Register - Write Only Register, Always Read as 0
  fields as SYSCTL_MGMT_M33ADC12B4MSPS1_RSTCTL
0xE2808 SYSCTL_MGMT_ANACOMP1_CLKCFG — IP Clock Configuration Register
  fields as SYSCTL_MGMT_RTC_CLKCFG
0xE2814 SYSCTL_MGMT_ANACOMP1_STAT ro — IP State Register - Read Only
  [16] RESETSTKY — IP has been Reset
    0=clear; 1=Set
0xE8800 SYSCTL_MGMT_VREF_PWREN — IP Enable Register
  [0] ENABLE — IP Enable
    0=Disable; 1=Enable
0xE8804 SYSCTL_MGMT_VREF_RSTCTL — Power Control Register - Write Only Register, Always Read as 0
  fields as SYSCTL_MGMT_M33ADC12B4MSPS1_RSTCTL
0xE8814 SYSCTL_MGMT_VREF_STAT ro — IP State Register - Read Only
  [16] RESETSTKY — IP has been Reset
    0=clear; 1=Set
{0xF0800+0x2000*i} SYSCTL_MGMT_GPIO{i}_PWREN (i=0..2) — IP Enable Register
  [0] ENABLE — IP Enable
    0=Disable; 1=Enable
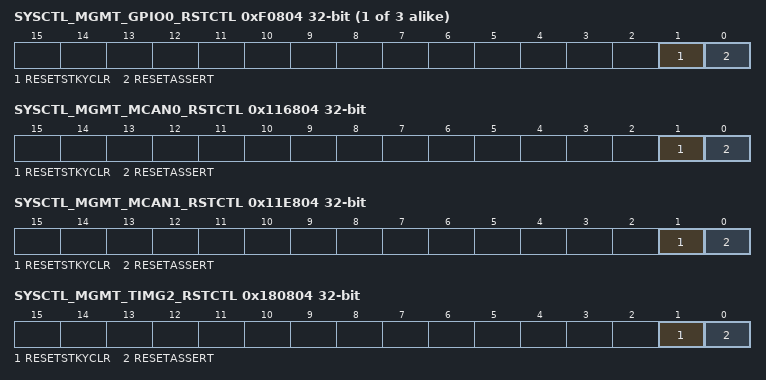
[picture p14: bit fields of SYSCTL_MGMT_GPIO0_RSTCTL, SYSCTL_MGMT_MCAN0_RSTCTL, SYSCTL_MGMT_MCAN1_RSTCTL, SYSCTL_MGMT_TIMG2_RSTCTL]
{0xF0804+0x2000*i} SYSCTL_MGMT_GPIO{i}_RSTCTL (i=0..2) — Power Control Register - Write Only Register, Always Read as 0
  fields as SYSCTL_MGMT_M33ADC12B4MSPS1_RSTCTL
{0xF0814+0x2000*i} SYSCTL_MGMT_GPIO{i}_STAT ro (i=0..2) — IP State Register - Read Only
  [16] RESETSTKY — IP has been Reset
    0=clear; 1=Set
0x116800 SYSCTL_MGMT_MCAN0_PWREN — IP Enable Register
  [0] ENABLE — IP Enable
    0=Disable; 1=Enable
0x116804 SYSCTL_MGMT_MCAN0_RSTCTL — Power Control Register - Write Only Register, Always Read as 0
  fields as SYSCTL_MGMT_M33ADC12B4MSPS1_RSTCTL
0x116814 SYSCTL_MGMT_MCAN0_STAT ro — IP State Register - Read Only
  [16] RESETSTKY — IP has been Reset
    0=clear; 1=Set
0x11E800 SYSCTL_MGMT_MCAN1_PWREN — IP Enable Register
  [0] ENABLE — IP Enable
    0=Disable; 1=Enable
0x11E804 SYSCTL_MGMT_MCAN1_RSTCTL — Power Control Register - Write Only Register, Always Read as 0
  fields as SYSCTL_MGMT_M33ADC12B4MSPS1_RSTCTL
0x11E814 SYSCTL_MGMT_MCAN1_STAT ro — IP State Register - Read Only
  [16] RESETSTKY — IP has been Reset
    0=clear; 1=Set
0x180800 SYSCTL_MGMT_TIMG2_PWREN — IP Enable Register
  [0] ENABLE — IP Enable
    0=Disable; 1=Enable
0x180804 SYSCTL_MGMT_TIMG2_RSTCTL — Power Control Register - Write Only Register, Always Read as 0
  fields as SYSCTL_MGMT_M33ADC12B4MSPS1_RSTCTL
0x180814 SYSCTL_MGMT_TIMG2_STAT ro — IP State Register - Read Only
  [16] RESETSTKY — IP has been Reset
    0=clear; 1=Set
0x182800 SYSCTL_MGMT_TIMG3_PWREN — IP Enable Register
  [0] ENABLE — IP Enable
    0=Disable; 1=Enable
0x182804 SYSCTL_MGMT_TIMG3_RSTCTL — Power Control Register - Write Only Register, Always Read as 0
  fields as SYSCTL_MGMT_M33ADC12B4MSPS1_RSTCTL
0x182814 SYSCTL_MGMT_TIMG3_STAT ro — IP State Register - Read Only
  [16] RESETSTKY — IP has been Reset
    0=clear; 1=Set
0x184800 SYSCTL_MGMT_TIMG8_PWREN — IP Enable Register
  [0] ENABLE — IP Enable
    0=Disable; 1=Enable
0x184804 SYSCTL_MGMT_TIMG8_RSTCTL — Power Control Register - Write Only Register, Always Read as 0
  fields as SYSCTL_MGMT_M33ADC12B4MSPS1_RSTCTL
0x184814 SYSCTL_MGMT_TIMG8_STAT ro — IP State Register - Read Only
  [16] RESETSTKY — IP has been Reset
    0=clear; 1=Set
0x186800 SYSCTL_MGMT_TIMG9_PWREN — IP Enable Register
  [0] ENABLE — IP Enable
    0=Disable; 1=Enable
0x186804 SYSCTL_MGMT_TIMG9_RSTCTL — Power Control Register - Write Only Register, Always Read as 0
  fields as SYSCTL_MGMT_M33ADC12B4MSPS1_RSTCTL
0x186814 SYSCTL_MGMT_TIMG9_STAT ro — IP State Register - Read Only
  [16] RESETSTKY — IP has been Reset
    0=clear; 1=Set
0x188800 SYSCTL_MGMT_TIMG12_PWREN — IP Enable Register
  [0] ENABLE — IP Enable
    0=Disable; 1=Enable
0x188804 SYSCTL_MGMT_TIMG12_RSTCTL — Power Control Register - Write Only Register, Always Read as 0
  fields as SYSCTL_MGMT_M33ADC12B4MSPS1_RSTCTL
0x188814 SYSCTL_MGMT_TIMG12_STAT ro — IP State Register - Read Only
  [16] RESETSTKY — IP has been Reset
    0=clear; 1=Set
0x1A0800 SYSCTL_MGMT_I2S0_PWREN — IP Enable Register
  [0] ENABLE — IP Enable
    0=Disable; 1=Enable
0x1A0804 SYSCTL_MGMT_I2S0_RSTCTL — Power Control Register - Write Only Register, Always Read as 0
  fields as SYSCTL_MGMT_M33ADC12B4MSPS1_RSTCTL
0x1A0808 SYSCTL_MGMT_I2S0_CLKCFG — IP Clock Configuration Register
  [1:0] DAICLK — Audio Clock
    0=SYSOSC; 1=HFCLK; 2=PLL; 3=EXTCLK
0x1A0814 SYSCTL_MGMT_I2S0_STAT ro — IP State Register - Read Only
  [16] RESETSTKY — IP has been Reset
    0=clear; 1=Set
0x1A2800 SYSCTL_MGMT_I2S1_PWREN — IP Enable Register
  [0] ENABLE — IP Enable
    0=Disable; 1=Enable
0x1A2804 SYSCTL_MGMT_I2S1_RSTCTL — Power Control Register - Write Only Register, Always Read as 0
  fields as SYSCTL_MGMT_M33ADC12B4MSPS1_RSTCTL
0x1A2808 SYSCTL_MGMT_I2S1_CLKCFG — IP Clock Configuration Register
  [1:0] DAICLK — Audio Clock
    0=SYSOSC; 1=HFCLK; 2=PLL; 3=EXTCLK
0x1A2814 SYSCTL_MGMT_I2S1_STAT ro — IP State Register - Read Only
  [16] RESETSTKY — IP has been Reset
    0=clear; 1=Set
0x1B0800 SYSCTL_MGMT_AES_PWREN — IP Enable Register
  [0] ENABLE — IP Enable
    0=Disable; 1=Enable
0x1B0804 SYSCTL_MGMT_AES_RSTCTL — Power Control Register - Write Only Register, Always Read as 0
  fields as SYSCTL_MGMT_M33ADC12B4MSPS1_RSTCTL
0x1B0814 SYSCTL_MGMT_AES_STAT ro — IP State Register - Read Only
  [16] RESETSTKY — IP has been Reset
    0=clear; 1=Set
0x1B2800 SYSCTL_MGMT_CRC0_PWREN — IP Enable Register
  [0] ENABLE — IP Enable
    0=Disable; 1=Enable
0x1B2804 SYSCTL_MGMT_CRC0_RSTCTL — Power Control Register - Write Only Register, Always Read as 0
  fields as SYSCTL_MGMT_M33ADC12B4MSPS1_RSTCTL
0x1B2814 SYSCTL_MGMT_CRC0_STAT ro — IP State Register - Read Only
  [16] RESETSTKY — IP has been Reset
    0=clear; 1=Set
0x1B4800 SYSCTL_MGMT_SHAW_PWREN — IP Enable Register
  [0] ENABLE — IP Enable
    0=Disable; 1=Enable
0x1B4804 SYSCTL_MGMT_SHAW_RSTCTL — Power Control Register - Write Only Register, Always Read as 0
  fields as SYSCTL_MGMT_M33ADC12B4MSPS1_RSTCTL
0x1B4814 SYSCTL_MGMT_SHAW_STAT ro — IP State Register - Read Only
  [16] RESETSTKY — IP has been Reset
    0=clear; 1=Set
0x1C0800 SYSCTL_MGMT_PKA_PWREN — IP Enable Register
  [0] ENABLE — IP Enable
    0=Disable; 1=Enable
0x1C0804 SYSCTL_MGMT_PKA_RSTCTL — Power Control Register - Write Only Register, Always Read as 0
  fields as SYSCTL_MGMT_M33ADC12B4MSPS1_RSTCTL
0x1C0814 SYSCTL_MGMT_PKA_STAT ro — IP State Register - Read Only
  [16] RESETSTKY — IP has been Reset
    0=clear; 1=Set
0x582800 SYSCTL_MGMT_S0U1_UNICOMM_PWREN — IP Enable Register
  [0] ENABLE — IP Enable
    0=Disable; 1=Enable
0x582804 SYSCTL_MGMT_S0U1_UNICOMM_RSTCTL — Power Control Register - Write Only Register, Always Read as 0
  fields as SYSCTL_MGMT_M33ADC12B4MSPS1_RSTCTL
0x582808 SYSCTL_MGMT_S0U1_UNICOMM_CLKCFG — IP Clock Configuration Register
  fields as SYSCTL_MGMT_RTC_CLKCFG
0x582814 SYSCTL_MGMT_S0U1_UNICOMM_STAT ro — IP State Register - Read Only
  [16] RESETSTKY — IP has been Reset
    0=clear; 1=Set
0x584800 SYSCTL_MGMT_S0U2_UNICOMM_PWREN — IP Enable Register
  [0] ENABLE — IP Enable
    0=Disable; 1=Enable
0x584804 SYSCTL_MGMT_S0U2_UNICOMM_RSTCTL — Power Control Register - Write Only Register, Always Read as 0
  fields as SYSCTL_MGMT_M33ADC12B4MSPS1_RSTCTL
0x584808 SYSCTL_MGMT_S0U2_UNICOMM_CLKCFG — IP Clock Configuration Register
  fields as SYSCTL_MGMT_RTC_CLKCFG
0x584814 SYSCTL_MGMT_S0U2_UNICOMM_STAT ro — IP State Register - Read Only
  [16] RESETSTKY — IP has been Reset
    0=clear; 1=Set
0x680800 SYSCTL_MGMT_S1U0_UNICOMM_PWREN — IP Enable Register
  [0] ENABLE — IP Enable
    0=Disable; 1=Enable
0x680804 SYSCTL_MGMT_S1U0_UNICOMM_RSTCTL — Power Control Register - Write Only Register, Always Read as 0
  fields as SYSCTL_MGMT_M33ADC12B4MSPS1_RSTCTL
0x680814 SYSCTL_MGMT_S1U0_UNICOMM_STAT ro — IP State Register - Read Only
  [16] RESETSTKY — IP has been Reset
    0=clear; 1=Set
{0x680800+0x2000*i} SYSCTL_MGMT_S1U{i}_UNICOMM_PWREN (i=2..5) — IP Enable Register
  [0] ENABLE — IP Enable
    0=Disable; 1=Enable
{0x680804+0x2000*i} SYSCTL_MGMT_S1U{i}_UNICOMM_RSTCTL (i=2..5) — Power Control Register - Write Only Register, Always Read as 0
  fields as SYSCTL_MGMT_M33ADC12B4MSPS1_RSTCTL
{0x680814+0x2000*i} SYSCTL_MGMT_S1U{i}_UNICOMM_STAT ro (i=2..5) — IP State Register - Read Only
  [16] RESETSTKY — IP has been Reset
    0=clear; 1=Set
{0x780800+0x2000*i} SYSCTL_MGMT_S2U{i}_UNICOMM_PWREN (i=0..3) — IP Enable Register
  [0] ENABLE — IP Enable
    0=Disable; 1=Enable
{0x780804+0x2000*i} SYSCTL_MGMT_S2U{i}_UNICOMM_RSTCTL (i=0..3) — Power Control Register - Write Only Register, Always Read as 0
  fields as SYSCTL_MGMT_M33ADC12B4MSPS1_RSTCTL
{0x780814+0x2000*i} SYSCTL_MGMT_S2U{i}_UNICOMM_STAT ro (i=0..3) — IP State Register - Read Only
  [16] RESETSTKY — IP has been Reset
    0=clear; 1=Set
